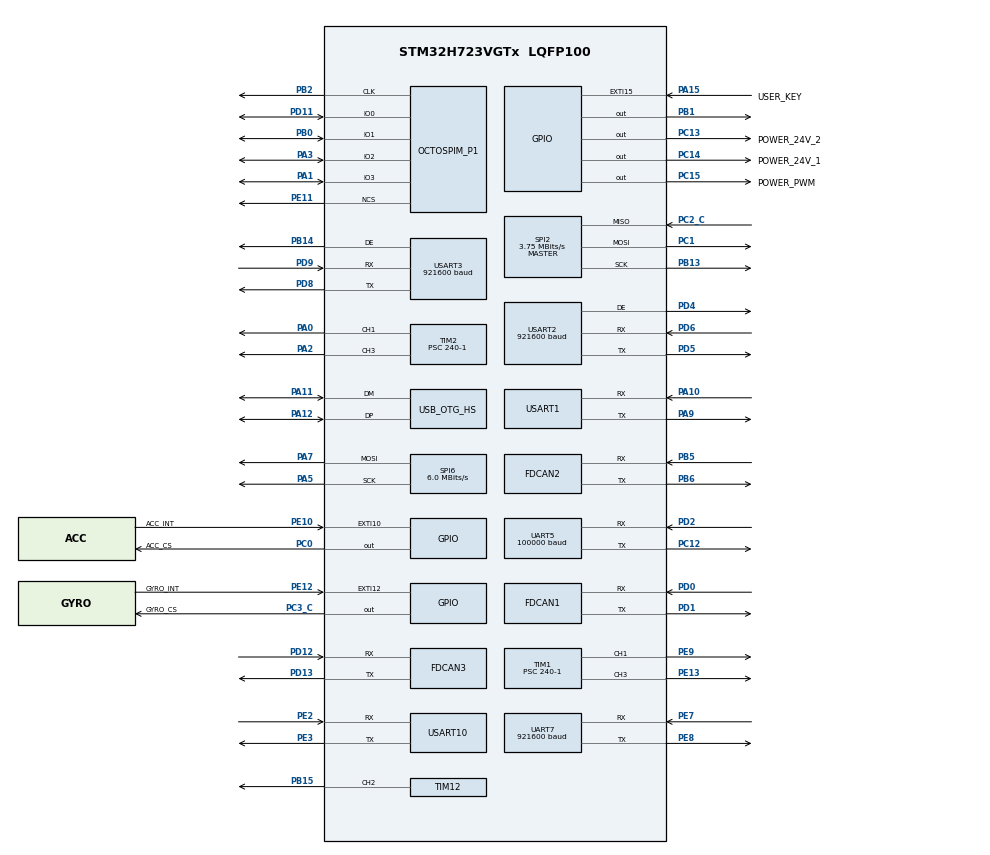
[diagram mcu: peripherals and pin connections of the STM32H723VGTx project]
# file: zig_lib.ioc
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CORTEX_M7.default_mode_Activation=1
Dma.Request0=USART1_RX
Dma.Request1=USART1_TX
Dma.Request2=UART5_RX
Dma.Request3=UART7_RX
Dma.Request4=USART2_RX
Dma.Request5=USART2_TX
Dma.Request6=USART3_RX
Dma.Request7=USART3_TX
Dma.Request8=USART10_RX
Dma.Request9=USART10_TX
Dma.UART5_RX.2.Direction=DMA_PERIPH_TO_MEMORY
Dma.UART5_RX.2.EventEnable=DISABLE
Dma.UART5_RX.2.FIFOMode=DMA_FIFOMODE_DISABLE
Dma.UART5_RX.2.Instance=DMA1_Stream7
Dma.UART5_RX.2.MemDataAlignment=DMA_MDATAALIGN_BYTE
Dma.UART5_RX.2.MemInc=DMA_MINC_ENABLE
Dma.UART5_RX.2.Mode=DMA_NORMAL
Dma.UART5_RX.2.PeriphDataAlignment=DMA_PDATAALIGN_BYTE
Dma.UART5_RX.2.PeriphInc=DMA_PINC_DISABLE
Dma.UART5_RX.2.Polarity=HAL_DMAMUX_REQ_GEN_RISING
Dma.UART5_RX.2.Priority=DMA_PRIORITY_LOW
Dma.UART5_RX.2.RequestNumber=1
Dma.UART5_RX.2.SignalID=NONE
Dma.UART5_RX.2.SyncEnable=DISABLE
Dma.UART5_RX.2.SyncPolarity=HAL_DMAMUX_SYNC_NO_EVENT
Dma.UART5_RX.2.SyncRequestNumber=1
Dma.UART5_RX.2.SyncSignalID=NONE
Dma.UART7_RX.3.Direction=DMA_PERIPH_TO_MEMORY
Dma.UART7_RX.3.EventEnable=DISABLE
Dma.UART7_RX.3.FIFOMode=DMA_FIFOMODE_DISABLE
Dma.UART7_RX.3.Instance=DMA1_Stream2
Dma.UART7_RX.3.MemDataAlignment=DMA_MDATAALIGN_BYTE
Dma.UART7_RX.3.MemInc=DMA_MINC_ENABLE
Dma.UART7_RX.3.Mode=DMA_NORMAL
Dma.UART7_RX.3.PeriphDataAlignment=DMA_PDATAALIGN_BYTE
Dma.UART7_RX.3.PeriphInc=DMA_PINC_DISABLE
Dma.UART7_RX.3.Polarity=HAL_DMAMUX_REQ_GEN_RISING
Dma.UART7_RX.3.Priority=DMA_PRIORITY_LOW
Dma.UART7_RX.3.RequestNumber=1
Dma.UART7_RX.3.SignalID=NONE
Dma.UART7_RX.3.SyncEnable=DISABLE
Dma.UART7_RX.3.SyncPolarity=HAL_DMAMUX_SYNC_NO_EVENT
Dma.UART7_RX.3.SyncRequestNumber=1
Dma.UART7_RX.3.SyncSignalID=NONE
Dma.USART10_RX.8.Direction=DMA_PERIPH_TO_MEMORY
Dma.USART10_RX.8.EventEnable=DISABLE
Dma.USART10_RX.8.FIFOMode=DMA_FIFOMODE_DISABLE
Dma.USART10_RX.8.Instance=DMA2_Stream0
Dma.USART10_RX.8.MemDataAlignment=DMA_MDATAALIGN_BYTE
Dma.USART10_RX.8.MemInc=DMA_MINC_ENABLE
Dma.USART10_RX.8.Mode=DMA_NORMAL
Dma.USART10_RX.8.PeriphDataAlignment=DMA_PDATAALIGN_BYTE
Dma.USART10_RX.8.PeriphInc=DMA_PINC_DISABLE
Dma.USART10_RX.8.Polarity=HAL_DMAMUX_REQ_GEN_RISING
Dma.USART10_RX.8.Priority=DMA_PRIORITY_LOW
Dma.USART10_RX.8.RequestNumber=1
Dma.USART10_RX.8.SignalID=NONE
Dma.USART10_RX.8.SyncEnable=DISABLE
Dma.USART10_RX.8.SyncPolarity=HAL_DMAMUX_SYNC_NO_EVENT
Dma.USART10_RX.8.SyncRequestNumber=1
Dma.USART10_RX.8.SyncSignalID=NONE
Dma.USART10_TX.9.Direction=DMA_MEMORY_TO_PERIPH
Dma.USART10_TX.9.EventEnable=DISABLE
Dma.USART10_TX.9.FIFOMode=DMA_FIFOMODE_DISABLE
Dma.USART10_TX.9.Instance=DMA2_Stream1
Dma.USART10_TX.9.MemDataAlignment=DMA_MDATAALIGN_BYTE
Dma.USART10_TX.9.MemInc=DMA_MINC_ENABLE
Dma.USART10_TX.9.Mode=DMA_NORMAL
Dma.USART10_TX.9.PeriphDataAlignment=DMA_PDATAALIGN_BYTE
Dma.USART10_TX.9.PeriphInc=DMA_PINC_DISABLE
Dma.USART10_TX.9.Polarity=HAL_DMAMUX_REQ_GEN_RISING
Dma.USART10_TX.9.Priority=DMA_PRIORITY_LOW
Dma.USART10_TX.9.RequestNumber=1
Dma.USART10_TX.9.SignalID=NONE
Dma.USART10_TX.9.SyncEnable=DISABLE
Dma.USART10_TX.9.SyncPolarity=HAL_DMAMUX_SYNC_NO_EVENT
Dma.USART10_TX.9.SyncRequestNumber=1
Dma.USART10_TX.9.SyncSignalID=NONE
Dma.USART1_RX.0.Direction=DMA_PERIPH_TO_MEMORY
Dma.USART1_RX.0.EventEnable=DISABLE
Dma.USART1_RX.0.FIFOMode=DMA_FIFOMODE_DISABLE
Dma.USART1_RX.0.Instance=DMA1_Stream0
Dma.USART1_RX.0.MemDataAlignment=DMA_MDATAALIGN_BYTE
Dma.USART1_RX.0.MemInc=DMA_MINC_ENABLE
Dma.USART1_RX.0.Mode=DMA_NORMAL
Dma.USART1_RX.0.PeriphDataAlignment=DMA_PDATAALIGN_BYTE
Dma.USART1_RX.0.PeriphInc=DMA_PINC_DISABLE
Dma.USART1_RX.0.Polarity=HAL_DMAMUX_REQ_GEN_RISING
Dma.USART1_RX.0.Priority=DMA_PRIORITY_LOW
Dma.USART1_RX.0.RequestNumber=1
Dma.USART1_RX.0.SignalID=NONE
Dma.USART1_RX.0.SyncEnable=DISABLE
Dma.USART1_RX.0.SyncPolarity=HAL_DMAMUX_SYNC_NO_EVENT
Dma.USART1_RX.0.SyncRequestNumber=1
Dma.USART1_RX.0.SyncSignalID=NONE
Dma.USART1_TX.1.Direction=DMA_MEMORY_TO_PERIPH
Dma.USART1_TX.1.EventEnable=DISABLE
Dma.USART1_TX.1.FIFOMode=DMA_FIFOMODE_DISABLE
Dma.USART1_TX.1.Instance=DMA1_Stream1
Dma.USART1_TX.1.MemDataAlignment=DMA_MDATAALIGN_BYTE
Dma.USART1_TX.1.MemInc=DMA_MINC_ENABLE
Dma.USART1_TX.1.Mode=DMA_NORMAL
Dma.USART1_TX.1.PeriphDataAlignment=DMA_PDATAALIGN_BYTE
Dma.USART1_TX.1.PeriphInc=DMA_PINC_DISABLE
Dma.USART1_TX.1.Polarity=HAL_DMAMUX_REQ_GEN_RISING
Dma.USART1_TX.1.Priority=DMA_PRIORITY_LOW
Dma.USART1_TX.1.RequestNumber=1
Dma.USART1_TX.1.SignalID=NONE
Dma.USART1_TX.1.SyncEnable=DISABLE
Dma.USART1_TX.1.SyncPolarity=HAL_DMAMUX_SYNC_NO_EVENT
Dma.USART1_TX.1.SyncRequestNumber=1
Dma.USART1_TX.1.SyncSignalID=NONE
Dma.USART2_RX.4.Direction=DMA_PERIPH_TO_MEMORY
Dma.USART2_RX.4.EventEnable=DISABLE
Dma.USART2_RX.4.FIFOMode=DMA_FIFOMODE_DISABLE
Dma.USART2_RX.4.Instance=DMA1_Stream3
Dma.USART2_RX.4.MemDataAlignment=DMA_MDATAALIGN_BYTE
Dma.USART2_RX.4.MemInc=DMA_MINC_ENABLE
Dma.USART2_RX.4.Mode=DMA_NORMAL
Dma.USART2_RX.4.PeriphDataAlignment=DMA_PDATAALIGN_BYTE
Dma.USART2_RX.4.PeriphInc=DMA_PINC_DISABLE
Dma.USART2_RX.4.Polarity=HAL_DMAMUX_REQ_GEN_RISING
Dma.USART2_RX.4.Priority=DMA_PRIORITY_LOW
Dma.USART2_RX.4.RequestNumber=1
Dma.USART2_RX.4.SignalID=NONE
Dma.USART2_RX.4.SyncEnable=DISABLE
Dma.USART2_RX.4.SyncPolarity=HAL_DMAMUX_SYNC_NO_EVENT
Dma.USART2_RX.4.SyncRequestNumber=1
Dma.USART2_RX.4.SyncSignalID=NONE
Dma.USART2_TX.5.Direction=DMA_MEMORY_TO_PERIPH
Dma.USART2_TX.5.EventEnable=DISABLE
Dma.USART2_TX.5.FIFOMode=DMA_FIFOMODE_DISABLE
Dma.USART2_TX.5.Instance=DMA1_Stream4
Dma.USART2_TX.5.MemDataAlignment=DMA_MDATAALIGN_BYTE
Dma.USART2_TX.5.MemInc=DMA_MINC_ENABLE
Dma.USART2_TX.5.Mode=DMA_NORMAL
Dma.USART2_TX.5.PeriphDataAlignment=DMA_PDATAALIGN_BYTE
Dma.USART2_TX.5.PeriphInc=DMA_PINC_DISABLE
Dma.USART2_TX.5.Polarity=HAL_DMAMUX_REQ_GEN_RISING
Dma.USART2_TX.5.Priority=DMA_PRIORITY_LOW
Dma.USART2_TX.5.RequestNumber=1
Dma.USART2_TX.5.SignalID=NONE
Dma.USART2_TX.5.SyncEnable=DISABLE
Dma.USART2_TX.5.SyncPolarity=HAL_DMAMUX_SYNC_NO_EVENT
Dma.USART2_TX.5.SyncRequestNumber=1
Dma.USART2_TX.5.SyncSignalID=NONE
Dma.USART3_RX.6.Direction=DMA_PERIPH_TO_MEMORY
Dma.USART3_RX.6.EventEnable=DISABLE
Dma.USART3_RX.6.FIFOMode=DMA_FIFOMODE_DISABLE
Dma.USART3_RX.6.Instance=DMA1_Stream5
Dma.USART3_RX.6.MemDataAlignment=DMA_MDATAALIGN_BYTE
Dma.USART3_RX.6.MemInc=DMA_MINC_ENABLE
Dma.USART3_RX.6.Mode=DMA_NORMAL
Dma.USART3_RX.6.PeriphDataAlignment=DMA_PDATAALIGN_BYTE
Dma.USART3_RX.6.PeriphInc=DMA_PINC_DISABLE
Dma.USART3_RX.6.Polarity=HAL_DMAMUX_REQ_GEN_RISING
Dma.USART3_RX.6.Priority=DMA_PRIORITY_LOW
Dma.USART3_RX.6.RequestNumber=1
Dma.USART3_RX.6.SignalID=NONE
Dma.USART3_RX.6.SyncEnable=DISABLE
Dma.USART3_RX.6.SyncPolarity=HAL_DMAMUX_SYNC_NO_EVENT
Dma.USART3_RX.6.SyncRequestNumber=1
Dma.USART3_RX.6.SyncSignalID=NONE
Dma.USART3_TX.7.Direction=DMA_MEMORY_TO_PERIPH
Dma.USART3_TX.7.EventEnable=DISABLE
Dma.USART3_TX.7.FIFOMode=DMA_FIFOMODE_DISABLE
Dma.USART3_TX.7.Instance=DMA1_Stream6
Dma.USART3_TX.7.MemDataAlignment=DMA_MDATAALIGN_BYTE
Dma.USART3_TX.7.MemInc=DMA_MINC_ENABLE
Dma.USART3_TX.7.Mode=DMA_NORMAL
Dma.USART3_TX.7.PeriphDataAlignment=DMA_PDATAALIGN_BYTE
Dma.USART3_TX.7.PeriphInc=DMA_PINC_DISABLE
Dma.USART3_TX.7.Polarity=HAL_DMAMUX_REQ_GEN_RISING
Dma.USART3_TX.7.Priority=DMA_PRIORITY_LOW
Dma.USART3_TX.7.RequestNumber=1
Dma.USART3_TX.7.SignalID=NONE
Dma.USART3_TX.7.SyncEnable=DISABLE
Dma.USART3_TX.7.SyncPolarity=HAL_DMAMUX_SYNC_NO_EVENT
Dma.USART3_TX.7.SyncRequestNumber=1
Dma.USART3_TX.7.SyncSignalID=NONE
FDCAN1.CalculateBaudRateNominal=1000000
FDCAN1.CalculateTimeBitNominal=1000
FDCAN1.CalculateTimeQuantumNominal=25.0
FDCAN1.DataPrescaler=3
FDCAN1.DataSyncJumpWidth=10
FDCAN1.DataTimeSeg1=29
FDCAN1.DataTimeSeg2=10
FDCAN1.FrameFormat=FDCAN_FRAME_CLASSIC
FDCAN1.NominalPrescaler=3
FDCAN1.NominalSyncJumpWidth=1
FDCAN1.NominalTimeSeg1=29
FDCAN1.NominalTimeSeg2=10
FDCAN1.RxFifo0ElmtsNbr=8
FDCAN1.StdFiltersNbr=21
FDCAN1.TxFifoQueueElmtsNbr=8
FDCAN2.CalculateBaudRateNominal=1000000
FDCAN2.CalculateTimeBitNominal=1000
FDCAN2.CalculateTimeQuantumNominal=25.0
FDCAN2.DataPrescaler=3
FDCAN2.DataSyncJumpWidth=10
FDCAN2.DataTimeSeg1=29
FDCAN2.DataTimeSeg2=10
FDCAN2.MessageRAMOffset=0x406
FDCAN2.NominalPrescaler=3
FDCAN2.NominalTimeSeg1=29
FDCAN2.NominalTimeSeg2=10
FDCAN2.RxFifo0ElmtsNbr=8
FDCAN2.RxFifo1ElmtsNbr=0
FDCAN2.StdFiltersNbr=21
FDCAN2.TxFifoQueueElmtsNbr=8
FDCAN3.CalculateBaudRateNominal=1000000
FDCAN3.CalculateTimeBitNominal=1000
FDCAN3.CalculateTimeQuantumNominal=25.0
FDCAN3.DataPrescaler=3
FDCAN3.DataSyncJumpWidth=10
FDCAN3.DataTimeSeg1=29
FDCAN3.DataTimeSeg2=1
FDCAN3.MessageRAMOffset=0x812
FDCAN3.NominalPrescaler=3
FDCAN3.NominalTimeSeg1=29
FDCAN3.NominalTimeSeg2=10
FDCAN3.RxFifo0ElmtsNbr=8
FDCAN3.RxFifo1ElmtsNbr=0
FDCAN3.StdFiltersNbr=21
FDCAN3.TxFifoQueueElmtsNbr=8
Mcu.Family=STM32H7
Mcu.Name=STM32H723VGTx
Mcu.Package=LQFP100
NVIC.DMA1_Stream0_IRQn=true\:0\:0\:false\:false\:true\:false\:true\:true
NVIC.DMA1_Stream1_IRQn=true\:0\:0\:false\:false\:true\:false\:true\:true
NVIC.DMA1_Stream2_IRQn=true\:0\:0\:false\:false\:true\:false\:true\:true
NVIC.DMA1_Stream3_IRQn=true\:0\:0\:false\:false\:true\:false\:true\:true
NVIC.DMA1_Stream4_IRQn=true\:0\:0\:false\:false\:true\:false\:true\:true
NVIC.DMA1_Stream5_IRQn=true\:0\:0\:false\:false\:true\:false\:true\:true
NVIC.DMA1_Stream6_IRQn=true\:0\:0\:false\:false\:true\:false\:true\:true
NVIC.DMA1_Stream7_IRQn=true\:0\:0\:false\:false\:true\:false\:true\:true
NVIC.DMA2_Stream0_IRQn=true\:0\:0\:false\:false\:true\:false\:true\:true
NVIC.DMA2_Stream1_IRQn=true\:0\:0\:false\:false\:true\:false\:true\:true
NVIC.EXTI15_10_IRQn=true\:0\:0\:false\:false\:true\:true\:true\:true
NVIC.FDCAN1_IT0_IRQn=true\:0\:0\:false\:false\:true\:true\:true\:true
NVIC.FDCAN1_IT1_IRQn=true\:0\:0\:false\:false\:true\:true\:true\:true
NVIC.FDCAN2_IT0_IRQn=true\:0\:0\:false\:false\:true\:true\:true\:true
NVIC.FDCAN2_IT1_IRQn=true\:0\:0\:false\:false\:true\:true\:true\:true
NVIC.FDCAN3_IT0_IRQn=true\:0\:0\:false\:false\:true\:true\:true\:true
NVIC.FDCAN3_IT1_IRQn=true\:0\:0\:false\:false\:true\:true\:true\:true
NVIC.FPU_IRQn=true\:0\:0\:false\:false\:true\:true\:false\:true
NVIC.OTG_HS_IRQn=true\:0\:0\:false\:false\:true\:true\:true\:true
NVIC.PriorityGroup=NVIC_PRIORITYGROUP_4
NVIC.UART5_IRQn=true\:0\:0\:false\:false\:true\:true\:true\:true
NVIC.UART7_IRQn=true\:0\:0\:false\:false\:true\:true\:true\:true
NVIC.USART10_IRQn=true\:0\:0\:false\:false\:true\:true\:true\:true
NVIC.USART1_IRQn=true\:0\:0\:false\:false\:true\:true\:true\:true
NVIC.USART2_IRQn=true\:0\:0\:false\:false\:true\:true\:true\:true
NVIC.USART3_IRQn=true\:0\:0\:false\:false\:true\:true\:true\:true
OCTOSPI2.ClockMode=HAL_OSPI_CLOCK_MODE_3
OCTOSPI2.ClockPrescaler=3
OCTOSPI2.DeviceSize=23
OCTOSPI2.FifoThreshold=8
OCTOSPI2.SampleShifting=HAL_OSPI_SAMPLE_SHIFTING_HALFCYCLE
PA0.GPIO_PuPd=GPIO_NOPULL
PA0.Signal=S_TIM2_CH1_ETR
PA1.Mode=OCTOSPI2_IOL_Port1L
PA1.Signal=OCTOSPIM_P1_IO3
PA10.Mode=Asynchronous
PA10.Signal=USART1_RX
PA11.Mode=Device_Only_FS
PA11.Signal=USB_OTG_HS_DM
PA12.Mode=Device_Only_FS
PA12.Signal=USB_OTG_HS_DP
PA13(JTMS/SWDIO).Mode=Serial_Wire
PA13(JTMS/SWDIO).Signal=DEBUG_JTMS-SWDIO
PA14(JTCK/SWCLK).Mode=Serial_Wire
PA14(JTCK/SWCLK).Signal=DEBUG_JTCK-SWCLK
PA15(JTDI).GPIO_Label=USER_KEY
PA15(JTDI).GPIO_ModeDefaultEXTI=GPIO_MODE_IT_RISING_FALLING
PA15(JTDI).Signal=GPXTI15
PA2.Signal=S_TIM2_CH3
PA3.Mode=OCTOSPI2_IOL_Port1L
PA3.Signal=OCTOSPIM_P1_IO2
PA5.GPIO_Speed=GPIO_SPEED_FREQ_VERY_HIGH
PA5.Mode=TX_Only_Simplex_Unidirect_Master
PA5.Signal=SPI6_SCK
PA7.GPIO_Speed=GPIO_SPEED_FREQ_VERY_HIGH
PA7.Mode=TX_Only_Simplex_Unidirect_Master
PA7.Signal=SPI6_MOSI
PA9.Mode=Asynchronous
PA9.Signal=USART1_TX
PB0.Mode=OCTOSPI2_IOL_Port1L
PB0.Signal=OCTOSPIM_P1_IO1
PB1.GPIO_PuPd=GPIO_PULLDOWN
PB1.Signal=GPIO_Output
PB13.Mode=Full_Duplex_Master
PB13.Signal=SPI2_SCK
PB14.Mode=Hardware Flow Control (RS485)
PB14.Signal=USART3_DE
PB15.Signal=S_TIM12_CH2
PB2.Mode=O2_P1_CLK
PB2.Signal=OCTOSPIM_P1_CLK
PB5.Mode=FDCAN_Activate
PB5.Signal=FDCAN2_RX
PB6.Mode=FDCAN_Activate
PB6.Signal=FDCAN2_TX
PC0.GPIO_Label=ACC_CS
PC0.GPIO_Speed=GPIO_SPEED_FREQ_VERY_HIGH
PC0.PinState=GPIO_PIN_SET
PC0.Signal=GPIO_Output
PC1.Mode=Full_Duplex_Master
PC1.Signal=SPI2_MOSI
PC12.Mode=Asynchronous
PC12.Signal=UART5_TX
PC13.GPIO_Label=POWER_24V_2
PC13.PinState=GPIO_PIN_SET
PC13.Signal=GPIO_Output
PC14-OSC32_IN.GPIO_Label=POWER_24V_1
PC14-OSC32_IN.PinState=GPIO_PIN_SET
PC14-OSC32_IN.Signal=GPIO_Output
PC15-OSC32_OUT.GPIO_Label=POWER_PWM
PC15-OSC32_OUT.PinState=GPIO_PIN_RESET
PC15-OSC32_OUT.Signal=GPIO_Output
PC2_C.Mode=Full_Duplex_Master
PC2_C.Signal=SPI2_MISO
PC3_C.GPIO_Label=GYRO_CS
PC3_C.GPIO_Speed=GPIO_SPEED_FREQ_VERY_HIGH
PC3_C.Signal=GPIO_Output
PD0.Mode=FDCAN_Activate
PD0.Signal=FDCAN1_RX
PD1.Mode=FDCAN_Activate
PD1.Signal=FDCAN1_TX
PD11.Mode=OCTOSPI2_IOL_Port1L
PD11.Signal=OCTOSPIM_P1_IO0
PD12.Mode=FDCAN_Activate
PD12.Signal=FDCAN3_RX
PD13.Mode=FDCAN_Activate
PD13.Signal=FDCAN3_TX
PD2.Mode=Asynchronous
PD2.Signal=UART5_RX
PD4.Mode=Hardware Flow Control (RS485)
PD4.Signal=USART2_DE
PD5.Mode=Asynchronous
PD5.Signal=USART2_TX
PD6.Mode=Asynchronous
PD6.Signal=USART2_RX
PD8.Mode=Asynchronous
PD8.Signal=USART3_TX
PD9.Mode=Asynchronous
PD9.Signal=USART3_RX
PE10.GPIO_Label=ACC_INT
PE10.Signal=GPXTI10
PE11.Mode=OCTOSPI2_Port1_NCS
PE11.Signal=OCTOSPIM_P1_NCS
PE12.GPIO_Label=GYRO_INT
PE12.Signal=GPXTI12
PE13.Signal=S_TIM1_CH3
PE2.Mode=Asynchronous
PE2.Signal=USART10_RX
PE3.Mode=Asynchronous
PE3.Signal=USART10_TX
PE7.Mode=Asynchronous
PE7.Signal=UART7_RX
PE8.Mode=Asynchronous
PE8.Signal=UART7_TX
PE9.Signal=S_TIM1_CH1
PH0-OSC_IN.Mode=HSE-External-Oscillator
PH0-OSC_IN.Signal=RCC_OSC_IN
PH1-OSC_OUT.Mode=HSE-External-Oscillator
PH1-OSC_OUT.Signal=RCC_OSC_OUT
ProjectManager.HeapSize=0x200
ProjectManager.StackSize=0x400
ProjectManager.TargetToolchain=STM32CubeIDE
RCC.ADCFreq_Value=96000000
RCC.APB1Freq_Value=120000000
RCC.APB2Freq_Value=120000000
RCC.APB3Freq_Value=120000000
RCC.APB4Freq_Value=120000000
RCC.CortexFreq_Value=480000000
RCC.D1PPRE=RCC_APB3_DIV2
RCC.D2PPRE1=RCC_APB1_DIV2
RCC.D2PPRE2=RCC_APB2_DIV2
RCC.D3PPRE=RCC_APB4_DIV2
RCC.DIVM1=2
RCC.DIVM2=2
RCC.DIVN1=40
RCC.DIVN2=16
RCC.DIVP1=1
RCC.DIVQ1=4
RCC.HCLKFreq_Value=240000000
RCC.HPRE=RCC_HCLK_DIV2
RCC.HSE_VALUE=24000000
RCC.PLL2FRACN=0
RCC.PLL3FRACN=0
RCC.PLLFRACN=0
RCC.PLLSourceVirtual=RCC_PLLSOURCE_HSE
RCC.SPI6CLockSelection=RCC_SPI6CLKSOURCE_HSE
RCC.SYSCLKFreq_VALUE=480000000
RCC.SYSCLKSource=RCC_SYSCLKSOURCE_PLLCLK
RCC.USBCLockSelection=RCC_USBCLKSOURCE_HSI48
RCC.USBFreq_Value=48000000
SH.S_TIM12_CH2.0=TIM12_CH2,PWM Generation2 CH2
SH.S_TIM1_CH1.0=TIM1_CH1,PWM Generation1 CH1
SH.S_TIM1_CH3.0=TIM1_CH3,PWM Generation3 CH3
SH.S_TIM2_CH1_ETR.0=TIM2_CH1,PWM Generation1 CH1
SH.S_TIM2_CH3.0=TIM2_CH3,PWM Generation3 CH3
SPI2.BaudRatePrescaler=SPI_BAUDRATEPRESCALER_32
SPI2.CLKPhase=SPI_PHASE_2EDGE
SPI2.CLKPolarity=SPI_POLARITY_HIGH
SPI2.CalculateBaudRate=3.75 MBits/s
SPI2.DataSize=SPI_DATASIZE_8BIT
SPI2.Direction=SPI_DIRECTION_2LINES
SPI2.Mode=SPI_MODE_MASTER
SPI2.VirtualType=VM_MASTER
SPI6.BaudRatePrescaler=SPI_BAUDRATEPRESCALER_4
SPI6.CLKPhase=SPI_PHASE_2EDGE
SPI6.CalculateBaudRate=6.0 MBits/s
SPI6.DataSize=SPI_DATASIZE_8BIT
SPI6.Direction=SPI_DIRECTION_2LINES_TXONLY
SPI6.Mode=SPI_MODE_MASTER
SPI6.VirtualType=VM_MASTER
STMicroelectronics.X-CUBE-ALGOBUILD.1.4.0.LibraryCcDSPOoLibraryJjDSPOoLibrary=true
TIM1.AutoReloadPreload=TIM_AUTORELOAD_PRELOAD_ENABLE
TIM1.Channel-PWM\ Generation1\ CH1=TIM_CHANNEL_1
TIM1.Channel-PWM\ Generation3\ CH3=TIM_CHANNEL_3
TIM1.Period=20000-1
TIM1.Prescaler=240-1
TIM12.Channel-PWM\ Generation2\ CH2=TIM_CHANNEL_2
TIM12.Prescaler=240-1
TIM2.AutoReloadPreload=TIM_AUTORELOAD_PRELOAD_ENABLE
TIM2.Channel-PWM\ Generation1\ CH1=TIM_CHANNEL_1
TIM2.Channel-PWM\ Generation3\ CH3=TIM_CHANNEL_3
TIM2.Period=20000-1
TIM2.Prescaler=240-1
TIM2.Pulse-PWM\ Generation1\ CH1=0
UART5.BaudRate=100000
UART5.Mode=MODE_TX_RX
UART5.Parity=PARITY_EVEN
UART5.RxPinLevelInvertParam=UART_ADVFEATURE_RXINV_DISABLE
UART5.StopBits=UART_STOPBITS_1
UART5.WordLength=WORDLENGTH_9B
UART7.BaudRate=921600
UART7.Mode=MODE_TX_RX
USART1.FIFOMode=FIFOMODE_DISABLE
USART1.VirtualMode-Asynchronous=VM_ASYNC
USART10.VirtualMode=VM_ASYNC
USART2.BaudRate=921600
USART2.VirtualMode-Asynchronous=VM_ASYNC
USART2.VirtualMode-Hardware\ Flow\ Control\ (RS485)=VM_ASYNC
USART3.BaudRate=921600
USART3.VirtualMode-Asynchronous=VM_ASYNC
USART3.VirtualMode-Hardware\ Flow\ Control\ (RS485)=VM_ASYNC
USB_DEVICE.CLASS_NAME_HS=CDC
USB_DEVICE.VirtualMode=Cdc
USB_DEVICE.VirtualModeHS=Cdc_HS
USB_OTG_HS.VirtualMode-Device_Only_FS=Device_Only_FS
VP_MEMORYMAP_VS_MEMORYMAP.Mode=CurAppReg
VP_OCTOSPI2_VS_octo.Mode=octo_mode
VP_STMicroelectronics.X-CUBE-ALGOBUILD_VS_DSPOoLibraryJjLibrary_1.4.0_1.4.0.Mode=DSPOoLibraryJjLibrary
VP_TIM12_VS_ClockSourceINT.Mode=Internal
VP_TIM1_VS_ClockSourceINT.Mode=Internal
VP_TIM2_VS_ClockSourceINT.Mode=Internal
VP_USB_DEVICE_VS_USB_DEVICE_CDC_HS.Mode=CDC_HS
board=custom

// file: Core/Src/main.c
/* USER CODE BEGIN Header */
/**
  ******************************************************************************
  * @file           : main.c
  * @brief          : Main program body
  ******************************************************************************
  * @attention
  *
  * Copyright (c) 2026 STMicroelectronics.
  * All rights reserved.
  *
  * This software is licensed under terms that can be found in the LICENSE file
  * in the root directory of this software component.
  * If no LICENSE file comes with this software, it is provided AS-IS.
  *
  ******************************************************************************
  */
/* USER CODE END Header */
#include "main.h"
#include "dma.h"
#include "fdcan.h"
#include "octospi.h"
#include "spi.h"
#include "tim.h"
#include "usart.h"
#include "usb_device.h"
#include "gpio.h"

void SystemClock_Config(void);
static void MPU_Config(void);

/* USER CODE BEGIN 0 */
#ifndef USE_USER_MAIN
/* USER CODE END 0 */

int main(void)
{

  /* USER CODE BEGIN 1 */
#endif
#ifdef USE_USER_MAIN
void MX_Main_Init()
{
  /* USER CODE END 1 */

  /* MPU Configuration--------------------------------------------------------*/
  MPU_Config();

  /* MCU Configuration--------------------------------------------------------*/

  /* Reset of all peripherals, Initializes the Flash interface and the Systick. */
  HAL_Init();

  /* Configure the system clock */
  SystemClock_Config();

  /* Initialize all configured peripherals */
  MX_GPIO_Init();
  MX_DMA_Init();
  MX_FDCAN1_Init();
  MX_SPI6_Init();
  MX_USART1_UART_Init();
  MX_FDCAN2_Init();
  MX_FDCAN3_Init();
  MX_UART5_Init();
  MX_UART7_Init();
  MX_SPI2_Init();
  MX_USB_DEVICE_Init();
  MX_USART2_UART_Init();
  MX_USART3_UART_Init();
  MX_TIM2_Init();
  MX_TIM1_Init();
  MX_TIM12_Init();
  MX_OCTOSPI2_Init();
  MX_USART10_UART_Init();
  /* USER CODE BEGIN 2 */
#endif
#ifndef USE_USER_MAIN
  /* USER CODE END 2 */

  /* Infinite loop */
  while (1)
  {

    /* USER CODE BEGIN 3 */
  }
#endif
  /* USER CODE END 3 */
}

void SystemClock_Config(void)
{
  RCC_OscInitTypeDef RCC_OscInitStruct = {0};
  RCC_ClkInitTypeDef RCC_ClkInitStruct = {0};

  /** Supply configuration update enable
  */
  HAL_PWREx_ConfigSupply(PWR_LDO_SUPPLY);

  /** Configure the main internal regulator output voltage
  */
  __HAL_PWR_VOLTAGESCALING_CONFIG(PWR_REGULATOR_VOLTAGE_SCALE0);

  while(!__HAL_PWR_GET_FLAG(PWR_FLAG_VOSRDY)) {}

  /** Initializes the RCC Oscillators according to the specified parameters
  * in the RCC_OscInitTypeDef structure.
  */
  RCC_OscInitStruct.OscillatorType = RCC_OSCILLATORTYPE_HSI48|RCC_OSCILLATORTYPE_HSE;
  RCC_OscInitStruct.HSEState = RCC_HSE_ON;
  RCC_OscInitStruct.HSI48State = RCC_HSI48_ON;
  RCC_OscInitStruct.PLL.PLLState = RCC_PLL_ON;
  RCC_OscInitStruct.PLL.PLLSource = RCC_PLLSOURCE_HSE;
  RCC_OscInitStruct.PLL.PLLM = 2;
  RCC_OscInitStruct.PLL.PLLN = 40;
  RCC_OscInitStruct.PLL.PLLP = 1;
  RCC_OscInitStruct.PLL.PLLQ = 4;
  RCC_OscInitStruct.PLL.PLLR = 2;
  RCC_OscInitStruct.PLL.PLLRGE = RCC_PLL1VCIRANGE_3;
  RCC_OscInitStruct.PLL.PLLVCOSEL = RCC_PLL1VCOWIDE;
  RCC_OscInitStruct.PLL.PLLFRACN = 0;
  if (HAL_RCC_OscConfig(&RCC_OscInitStruct) != HAL_OK)
  {
    Error_Handler();
  }

  /** Initializes the CPU, AHB and APB buses clocks
  */
  RCC_ClkInitStruct.ClockType = RCC_CLOCKTYPE_HCLK|RCC_CLOCKTYPE_SYSCLK
                              |RCC_CLOCKTYPE_PCLK1|RCC_CLOCKTYPE_PCLK2
                              |RCC_CLOCKTYPE_D3PCLK1|RCC_CLOCKTYPE_D1PCLK1;
  RCC_ClkInitStruct.SYSCLKSource = RCC_SYSCLKSOURCE_PLLCLK;
  RCC_ClkInitStruct.SYSCLKDivider = RCC_SYSCLK_DIV1;
  RCC_ClkInitStruct.AHBCLKDivider = RCC_HCLK_DIV2;
  RCC_ClkInitStruct.APB3CLKDivider = RCC_APB3_DIV2;
  RCC_ClkInitStruct.APB1CLKDivider = RCC_APB1_DIV2;
  RCC_ClkInitStruct.APB2CLKDivider = RCC_APB2_DIV2;
  RCC_ClkInitStruct.APB4CLKDivider = RCC_APB4_DIV2;

  if (HAL_RCC_ClockConfig(&RCC_ClkInitStruct, FLASH_LATENCY_3) != HAL_OK)
  {
    Error_Handler();
  }
}

 /* MPU Configuration */

void MPU_Config(void)
{
  MPU_Region_InitTypeDef MPU_InitStruct = {0};

  /* Disables the MPU */
  HAL_MPU_Disable();

  /** Initializes and configures the Region and the memory to be protected
  */
  MPU_InitStruct.Enable = MPU_REGION_ENABLE;
  MPU_InitStruct.Number = MPU_REGION_NUMBER0;
  MPU_InitStruct.BaseAddress = 0x0;
  MPU_InitStruct.Size = MPU_REGION_SIZE_4GB;
  MPU_InitStruct.SubRegionDisable = 0x87;
  MPU_InitStruct.TypeExtField = MPU_TEX_LEVEL0;
  MPU_InitStruct.AccessPermission = MPU_REGION_NO_ACCESS;
  MPU_InitStruct.DisableExec = MPU_INSTRUCTION_ACCESS_DISABLE;
  MPU_InitStruct.IsShareable = MPU_ACCESS_SHAREABLE;
  MPU_InitStruct.IsCacheable = MPU_ACCESS_NOT_CACHEABLE;
  MPU_InitStruct.IsBufferable = MPU_ACCESS_NOT_BUFFERABLE;

  HAL_MPU_ConfigRegion(&MPU_InitStruct);
  /* Enables the MPU */
  HAL_MPU_Enable(MPU_PRIVILEGED_DEFAULT);

}

void Error_Handler(void)
{
  __disable_irq();
  while (1)
  {
  }
}
